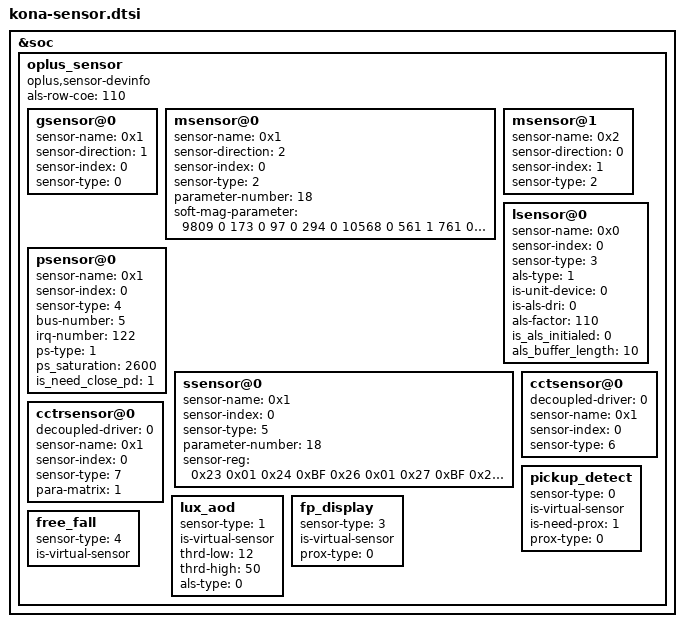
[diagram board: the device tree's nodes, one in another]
&soc {
	oplus_sensor {
		compatible = "oplus,sensor-devinfo";
		als-row-coe = <110>;
		/*enum {LSM6DSM = 0x01, BMI160 = 0x02, LSM6DS3 = 0x04};*/
		gsensor@0 {
			sensor-name = <0x1>;//LSM6DSM
			sensor-direction = <1>;
			sensor-index = <0>;//source num
			sensor-type = <0>;//OPPO_ACCEL
		};
		/* enum {AKM0991X = 0x01, MMC5603 = 0x02};*/
		msensor@0 {
			sensor-name = <0x1>;//AKM0991X
			sensor-direction = <2>;
			sensor-index = <0>;
			sensor-type = <2>;//OPPO_MAG
			parameter-number= <18>;
			//sensor-parameter = <2>;//0-useless;other- to differ special parameter
			soft-mag-parameter = <9809 0 173 0 97 0 294 0 10568 0 561 1 761 0 131 1 10676 0>;//e00 sign e01 sign ...
		};
		msensor@1 {
			sensor-name = <0x2>;//MMC5603
			sensor-direction = <0>;
			sensor-index = <1>;
			sensor-type = <2>;//OPPO_MAG

		};
		/*enum {STK3A5X=0x01,TCS3701=0x02,TCS3408=0x04};*/
		lsensor@0 {
			sensor-name = <0x0>;//TCS3408
			sensor-index = <0>;
			sensor-type = <3>;//OPPO_LIGHT
			als-type = <1>;//<1-normal;2-under screen;3-normal needed compensation>
			is-unit-device = <0>;//<1-alsps unit device;0-separate device>
			is-als-dri = <0>;//<0-polling 1-irq>
			als-factor = <110>;
			is_als_initialed = <0>;
			als_buffer_length = <10>;
		};
		psensor@0 {
			sensor-name = <0x1>;//STK33502
			sensor-index = <0>;
			sensor-type = <4>;//OPPO_PROXIMITY
			bus-number = <5>;
			irq-number = <122>;
			ps-type = <1>;
			ps_saturation = <2600>;
			is_need_close_pd = <1>;

		};
		/* enum {SX9324 = 0x01} */
		ssensor@0 {
			sensor-name = <0x1>; //SX9324
			sensor-index = <0>;
			sensor-type = <5>; //OPPO_SAR
			parameter-number = <18>;
			sensor-reg       = <0x23 0x01
					    0x24 0xBF
					    0x26 0x01
					    0x27 0xBF
					    0x2A 0x1F
					    0x30 0x0B
					    0x31 0x0B
					    0x36 0x18
					    0x37 0x17>; //override special reg
		};
		/* enum {tcs3408 = 0x01  stk37600 = 0x02} */
		cctsensor@0 {
			decoupled-driver = <0>; //0 - tcs3408 driver; 1 - oplus_cct driver
			sensor-name = <0x1>; //tcs3408
			sensor-index = <0>;
			sensor-type = <6>; //OPPO_CCT
		};
		cctrsensor@0 {
			decoupled-driver = <0>; //0 - tcs3408 driver; 1 - oplus_cct driver
			sensor-name = <0x1>; //tcs3408
			sensor-index = <0>;
			sensor-type = <7>; //OPPO_CCT_REAR
			para-matrix = <1>;//0-default
		};
		/*virtual sensor
		enum sensor_algo_id {
			OPPO_PICKUP_DETECT,
			OPPO_LUX_AOD,
			OPPO_TP_GESTURE,
			OPPO_FP_DISPLAY,
			OPPO_FREE_FALL,
			OPPO_CAMERA_PROTECT,
			SENSOR_ALGO_NUM
		}*/
		pickup_detect {
			sensor-type = <0>;//OPPO_PICKUP_DETECT
			is-virtual-sensor;
			is-need-prox = <1>;//0 - disable; 1 - enable
			prox-type = <0>;//prox_type: 0 - proximity; 1 - proximity_fake
		};
		lux_aod {
			sensor-type = <1>; //OPPO_LUX_AOD
			is-virtual-sensor;
			thrd-low = <12>;
			thrd-high = <50>;
			als-type = <0>; // 0 - ambient_light; 1 - wise_light
		};
		fp_display {
			sensor-type = <3>;//OPPO_FP_DISPLAY
			is-virtual-sensor;
			prox-type = <0>; //  0 - proximity; 1 - proximity_fake
		};
		free_fall {
			sensor-type = <4>;//OPPO_FREE_FALL
			is-virtual-sensor;
		};
	};
};
